# Secure_IoT register map
Vendor: Mindgrove Technologies Private Limited; Series: Mindgrove Silicon; File version: 1.0.0
CPU: VAJRA r1p9, little endian, MPU, FPU, double-precision FPU, I-cache, D-cache, 7 interrupt priority bits
Registers are 32-bit, read-write, reset 0x0 unless marked. A register's access mark holds for its fields unless they carry their own. Offsets are from the block's base; [hi:lo] are bit positions; {n}, {i} and the like mark numbered series.

## SHA256 — SHA256 algorithm accelerator
Base 0x03000000
0x00 SHA_INPUT 64-bit wo (reset mask 0xFFFFFFFF) — Input text register. Input is given 64 bits at a time.
0x80 SHA_OUTPUT 64-bit wo (reset mask 0xFFFFFFFF) — Output text register. Input is given 64 bits at a time.
0xC0 SHA_CTRL 8-bit — Control register
  [0] CONT_PREHASH — To continue the hash calculated from previous block to next block or not. 1 - continue from previous block. 0 - Initial prehash
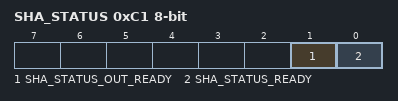
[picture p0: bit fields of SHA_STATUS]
0xC1 SHA_STATUS 8-bit ro — To read the status register
  [1] SHA_STATUS_OUT_READY — The output of the SHA is ready
  [0] SHA_STATUS_READY — Sha is ready to take another input

## RSA — RSA crypto accelerator
Base 0x05000000
0x00 RSA_INPUT 64-bit wo (reset mask 0xFFFFFFFF)
0x20 RSA_EXP 64-bit wo (reset mask 0xFFFFFFFF) — RSA exponent register
0x40 RSA_MOD 64-bit wo (reset mask 0xFFFFFFFF) — RSA modulus register
0x60 RSA_RSqrMODN 64-bit wo (reset mask 0xFFFFFFFF) — RSA (R^2) % N register
0x80 RSA_OUTPUT 64-bit ro (reset mask 0xFFFFFFFF)
0xC0 RSA_READY ro — RSA is ready to take another input and computation of previous is done

## QUADSPI0 — QuadSPI Interface 0
Base 0x00040000
Same registers: QUADSPI1 0x00040100
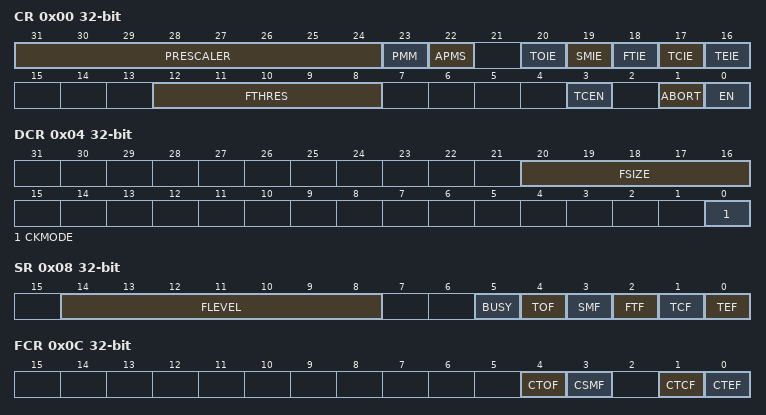
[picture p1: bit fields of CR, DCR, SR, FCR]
0x00 CR — Control Register
  [31:24] PRESCALER — Clock prescaler
  [23] PMM — Polling match mode
  [22] APMS — Automatic poll mode stop
  [20] TOIE — TimeOut interrupt enable
  [19] SMIE — Status match interrupt enable
  [18] FTIE — FIFO threshold interrupt enable
  [17] TCIE — Transfer complete interrupt enable
  [16] TEIE — Transfer error interrupt enable
  [12:8] FTHRES — IFO threshold level
  [3] TCEN — Timeout counter enable
  [1] ABORT — QSPI Communication Abort request
  [0] EN — QSPI Communication Enable
0x04 DCR — Device Configuration Register
  [20:16] FSIZE — FLASH memory size
  [0] CKMODE — Mode 0 / mode 3
0x08 SR ro — Status Register
  [14:8] FLEVEL — FIFO level
  [5] BUSY
  [4] TOF — Timeout flag
  [3] SMF — Status match flag
  [2] FTF — FIFO threshold flag
  [1] TCF — Transfer complete flag
  [0] TEF — Transfer error flag
0x0C FCR — Flag Clear Register
  [4] CTOF — Clear timeout flag
  [3] CSMF — Clear status match flag
  [1] CTCF — Clear transfer complete flag
  [0] CTEF — Clear transfer error flag
0x10 DLR — data length register
  [31:0] DL — Data length
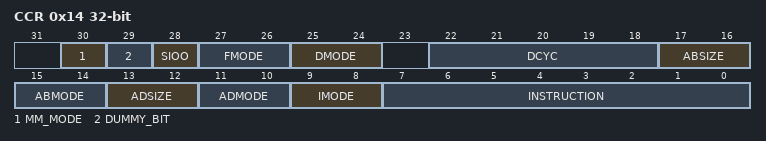
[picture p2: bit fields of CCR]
0x14 CCR — communication configuration register
  [30] MM_MODE — Memory Mapped Mode. Default value 0. For XIP Mode, set 0, for RAM Mode, set 1.
  [29] DUMMY_BIT — Set value 1 to send Dummy Cycles. Default 0
  [28] SIOO — Send instruction only once mode
  [27:26] FMODE — Functional mode
  [25:24] DMODE — Data mode
  [22:18] DCYC — Number of dummy cycles
  [17:16] ABSIZE — Alternate bytes size
  [15:14] ABMODE — Alternate bytes mode
  [13:12] ADSIZE — Address size
  [11:10] ADMODE — Address mode
  [9:8] IMODE — Instruction mode
  [7:0] INSTRUCTION
0x18 AR — Address Register
  [31:0] ADDRESS
0x1C ABR — Alternate Byte Register
  [31:0] ALTERNATE — Alternate Byte
0x20 DR — Data Register
  [31:0] DATA

## ITRACE — Instruction Trace
Base 0x00060000
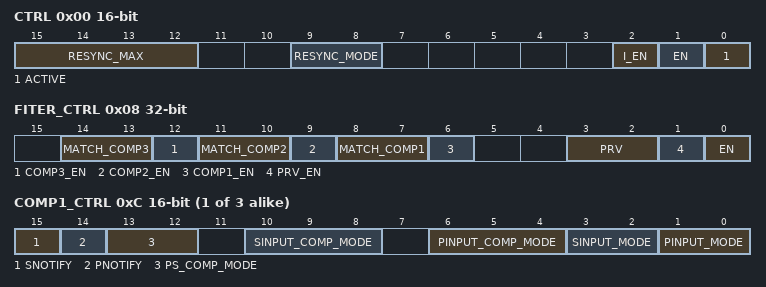
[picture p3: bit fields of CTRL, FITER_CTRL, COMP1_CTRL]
0x00 CTRL 16-bit — Itrace control register
  [15:12] RESYNC_MAX — Sets the resync interval time.
  [9:8] RESYNC_MODE — Sets the resync packet mode. 0-Not supported, 1-Trace packet count, 2-Every clock, 3-Instruction retired
  [2] I_EN — Enables the Instruction trace
  [1] EN — Enables the trace
  [0] ACTIVE — Indicates whether trace is active or not. Used for gating.
0x08 FITER_CTRL — Instruction filter control
  [14:13] MATCH_COMP3 — Mentions which comparator output to use for this 3rd filter
  [12] COMP3_EN — Enable the first comparator
  [11:10] MATCH_COMP2 — Mentions which comparator output to use for this 2nd filter
  [9] COMP2_EN — Enable the second comparator
  [8:7] MATCH_COMP1 — Mentions which comparator output to use for this 1st filter
  [6] COMP1_EN — Enable the first comparator
  [3:2] PRV — The privelege mode to filter when enabled
  [1] PRV_EN — Match privielge mode enable
  [0] EN — Filter enable
{0x8+4i} COMP{i}_CTRL 16-bit (i=1..3) — Control register for 1st comparator
  [15] SNOTIFY — Sends a support packet when secondary comparator matches
  [14] PNOTIFY — Sends a support packet when primary comparator matches
  [13:12] PS_COMP_MODE — The comparison to be performed between primary and secondary input.
  [10:8] SINPUT_COMP_MODE — Mentions the comparison to be done for secondary input. 0-equality, 1-not equal, 2-less than, 3-less than equal to, 4-greater than, 5-greater than equal to, 6-False, 7-True
  [6:4] PINPUT_COMP_MODE — Mentions the comparison to be done for primary input. 0-equality, 1-not equal, 2-less than, 3-less than equal to, 4-greater than, 5-greater than equal to, 6-False, 7-True
  [3:2] SINPUT_MODE — Secondary comparator input mode. 0: iaddr, 1: context, 2: tval, 3: daddr.
  [1:0] PINPUT_MODE — Primary comparator input mode. 0: iaddr, 1: context, 2: tval, 3: daddr.
0x18 COMP1_PMATCH_LOW — Comparator 1 primary match data: Low 32 bits
0x1C COMP1_PMATCH_HIGH — Comparator 1 primary match data: High 32 bits
0x20 COMP1_SMATCH_LOW — Comparator 1 secondary match data: Low 32 bits

## ITRACE_RAM — The RAM sink where all the trace packets are stored
Base 0x00060100
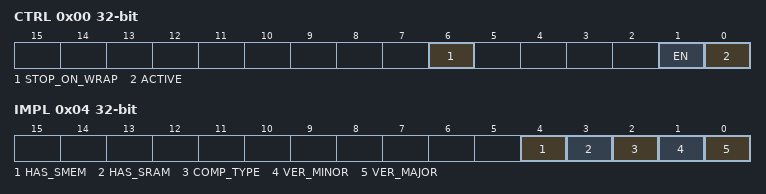
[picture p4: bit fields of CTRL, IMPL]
0x00 CTRL — Control register
  [6] STOP_ON_WRAP — Stop filling up packets into RAM when full
  [1] EN — Enables the RAM to take trace packets.
  [0] ACTIVE — Indicates whether RAM is active or not.
0x04 IMPL ro — Implementation details register
  [4] HAS_SMEM — Indicates whether SREM is present
  [3] HAS_SRAM — Indicates whether SRAM is present
  [2] COMP_TYPE — Trace RAM sink component type
  [1] VER_MINOR — Minor version number
  [0] VER_MAJOR — Major version number
0x10 START_LOW — The RAM start address register. Low 32 bits
0x14 START_HIGH — The RAM start address register. High 32 bits
0x18 LIMIT_LOW — The RAM end address register. Low 32 bits
0x1C LIMIT_HIGH — The RAM end address register. High 32 bits
0x20 WP_LOW — Write pointer of trace packet into RAM. Low 32 bits
0x24 WP_HIGH — Write pointer of trace packet into RAM. High 32 bits
0x28 RP_LOW — Read pointer of trace packet into RAM. Low 32 bits
0x2C RP_HIGH — Read pointer of trace packet into RAM. High 32 bits
0x40 DATA ro — RAM data is read by external host via this register.

## PLIC0 — Platform Level Interrupt Controller
Base 0x0C000000
{0x0+4i} PRIORITY{i} (i=0..63) — Priority register for interrupt source {i}
0x1000 PENDING_0_32 ro — Interrupt pending bits of sources 0-32
0x1004 PENDING_33_63 ro — Interrupt pending bits of sources 33-63
0x2000 INTR_EN_0_32 — Interrupt enable bits of sources 0-32
0x2004 INTR_EN_33_63 — Interrupt enable bits of sources 33-63
0x10000 PRIORITY_THRES — Priority threshold register
0x10004 INTR_COMPLETE — Interrupt claim/complete register
